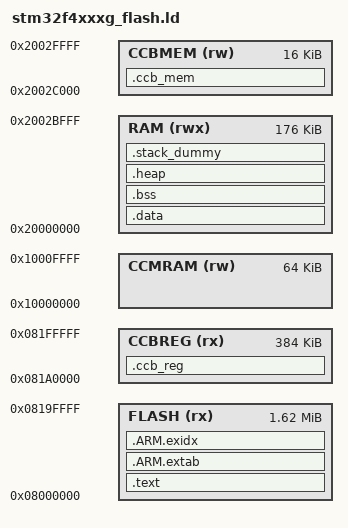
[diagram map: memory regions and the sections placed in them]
/**
  ******************************************************************************
  * @file    ccb_command.c
  * @author  Infonam Embedded Team
  * @version V1.1.0
  * @date    05-Mar-2015
  * @brief   This file provides CCB Command Parsers.
  ******************************************************************************
  ******************************************************************************
  *  History:
  *
  *  17.03.2015  DuongVT  First Version for the stm32f429ig, based on an 
  *                    	  example from the CMSIS packages of ARM.
  *****************************************************************************
  */

/* Entry Point */
ENTRY(Reset_Handler)

/*
 * Memory Spaces Definitions.
 *
 * Need modifying for a specific board. 
 *   FLASH.ORIGIN: starting address of flash
 *   FLASH.LENGTH: length of flash
 *   RAM.ORIGIN: starting address of RAM bank 0
 *   RAM.LENGTH: length of RAM bank 0
 *
 * The values below can be addressed in further linker scripts
 * using functions like 'ORIGIN(RAM)' or 'LENGTH(RAM)'.
 */
MEMORY
{
  FLASH (rx) : ORIGIN = 0x08000000, LENGTH = 2048K-384K
  CCBREG (rx): ORIGIN = 0x081A0000, LENGTH = 384K
  RAM (rwx)  : ORIGIN = 0x20000000, LENGTH = 192K-16K
  CCBMEM (rw): ORIGIN = 0x2002C000, LENGTH = 16K
  CCMRAM (rw): ORIGIN = 0x10000000, LENGTH = 64K
}

/* Library configurations */
GROUP(libgcc.a libc.a libm.a libnosys.a)

/* Linker script to place sections and symbol values. Should be used together
 * with other linker script that defines memory regions FLASH and RAM.
 * It references following symbols, which must be defined in code:
 *   Reset_Handler : Entry of reset handler
 * 
 * It defines following symbols, which code can use without definition:
 *   __exidx_start
 *   __exidx_end
 *   __etext
 *   __data_start__
 *   __preinit_array_start
 *   __preinit_array_end
 *   __init_array_start
 *   __init_array_end
 *   __fini_array_start
 *   __fini_array_end
 *   __data_end__
 *   __bss_start__
 *   __bss_end__
 *   __end__
 *   end
 *   __HeapLimit
 *   __StackLimit
 *   __StackTop
 *   __stack
 */
/* ENTRY(Reset_Handler) */

/*
 * The '__stack' definition is required by crt0, do not remove it.
 */
__stack = ORIGIN(RAM) + LENGTH(RAM);

/* Highest address of the user mode stack */
_estack = __stack; 	/* STM specific definition */

SECTIONS
{
	.text :
	{
		KEEP(*(.isr_vector))
		*(.text*)

		KEEP(*(.init))
		KEEP(*(.fini))

		/* .ctors */
		*crtbegin.o(.ctors)
		*crtbegin?.o(.ctors)
		*(EXCLUDE_FILE(*crtend?.o *crtend.o) .ctors)
		*(SORT(.ctors.*))
		*(.ctors)

		/* .dtors */
 		*crtbegin.o(.dtors)
 		*crtbegin?.o(.dtors)
 		*(EXCLUDE_FILE(*crtend?.o *crtend.o) .dtors)
 		*(SORT(.dtors.*))
 		*(.dtors)

		*(.rodata*)

		KEEP(*(.eh_frame*))
	} > FLASH
	
    .ccb_reg :
    {
        *(.ccb_reg)
    } > CCBREG
    
    .ccb_mem :
    {
       *(.ccb_mem)
    } > CCBMEM
	
	.ARM.extab : 
	{
		*(.ARM.extab* .gnu.linkonce.armextab.*)
	} > FLASH

	
	.ARM.exidx :
	{
		__exidx_start = .;
		*(.ARM.exidx* .gnu.linkonce.armexidx.*)
		__exidx_end = .;
	} > FLASH

	__etext = .;
		
	.data : AT (__etext)
	{
		__data_start__ = .;
		_sdata = __data_start__;
		*(vtable)
		*(.data*)

		. = ALIGN(4);
		/* preinit data */
		PROVIDE_HIDDEN (__preinit_array_start = .);
		KEEP(*(.preinit_array))
		PROVIDE_HIDDEN (__preinit_array_end = .);

		. = ALIGN(4);
		/* init data */
		PROVIDE_HIDDEN (__init_array_start = .);
		KEEP(*(SORT(.init_array.*)))
		KEEP(*(.init_array))
		PROVIDE_HIDDEN (__init_array_end = .);

		. = ALIGN(4);
		/* finit data */
		PROVIDE_HIDDEN (__fini_array_start = .);
		KEEP(*(SORT(.fini_array.*)))
		KEEP(*(.fini_array))
		PROVIDE_HIDDEN (__fini_array_end = .);

		. = ALIGN(4);
		/* All data end */
		__data_end__ = .;
		_edata = __data_end__;

	} > RAM

	_sidata = LOADADDR(.data);

	.bss :
	{
		. = ALIGN(4);
		__bss_start__ = .;
		_sbss = __bss_start__;
		*(.bss*)
		*(COMMON)
		. = ALIGN(4);
		__bss_end__ = .;
		_ebss = __bss_end__;
	} > RAM
	
	.heap :
	{
		. = ALIGN(4);
		__end__ = .;
		end = __end__;
		*(.heap*)
		. = ALIGN(4);
		__HeapLimit = .;
	} > RAM

	/* .stack_dummy section doesn't contains any symbols. It is only
	 * used for linker to calculate size of stack sections, and assign
	 * values to stack symbols later */
	.stack_dummy :
	{
		*(.stack)
	} > RAM

	/* Set stack top to end of RAM, and stack limit move down by
	 * size of stack_dummy section */
	__StackTop = ORIGIN(RAM) + LENGTH(RAM);
	__StackLimit = __StackTop - SIZEOF(.stack_dummy);
	PROVIDE(__stack = __StackTop);
	
	/* Check if data + heap + stack exceeds RAM limit */
	ASSERT(__StackLimit >= __HeapLimit, "region RAM overflowed with stack")
}

/*** EOF **/

